# ESW3120 register map
Vendor: Shanghai Eastsoft Microelectronics Co.,Ltd.; Series: ARMCM3; File version: 1.2
CPU: CM3 r2p1, little endian, MPU, no FPU, 4 interrupt priority bits
Registers are 32-bit, read-write, reset 0x0 unless marked. A register's access mark holds for its fields unless they carry their own. Offsets are from the block's base; [hi:lo] are bit positions; {n}, {i} and the like mark numbered series.

## DBGC
Base 0x4004A000
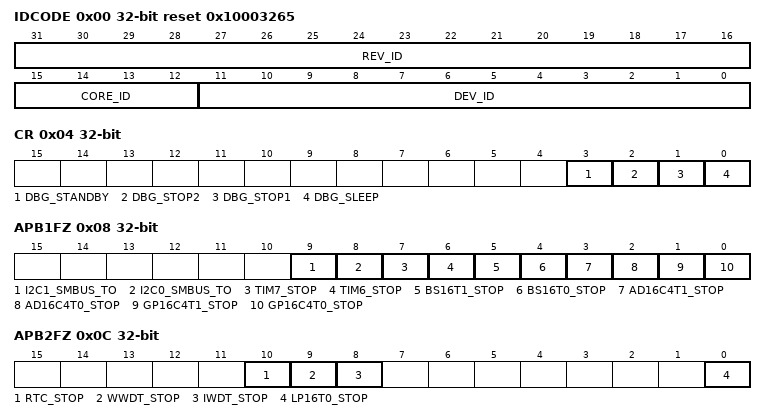
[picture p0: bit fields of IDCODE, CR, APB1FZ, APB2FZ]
0x00 IDCODE read reset 0x10003265
  [31:16] REV_ID, [15:12] CORE_ID, [11:0] DEV_ID
0x04 CR
  [3] DBG_STANDBY, [2] DBG_STOP2, [1] DBG_STOP1, [0] DBG_SLEEP
0x08 APB1FZ
  [9] I2C1_SMBUS_TO, [8] I2C0_SMBUS_TO, [7] TIM7_STOP, [6] TIM6_STOP, [5] BS16T1_STOP, [4] BS16T0_STOP, [3] AD16C4T1_STOP, [2] AD16C4T0_STOP, [1] GP16C4T1_STOP, [0] GP16C4T0_STOP
0x0C APB2FZ
  [10] RTC_STOP, [9] WWDT_STOP, [8] IWDT_STOP, [0] LP16T0_STOP
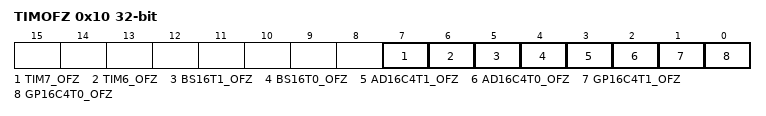
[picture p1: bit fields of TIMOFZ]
0x10 TIMOFZ
  [7] TIM7_OFZ, [6] TIM6_OFZ, [5] BS16T1_OFZ, [4] BS16T0_OFZ, [3] AD16C4T1_OFZ, [2] AD16C4T0_OFZ, [1] GP16C4T1_OFZ, [0] GP16C4T0_OFZ

## CRYPT
Base 0x40085800
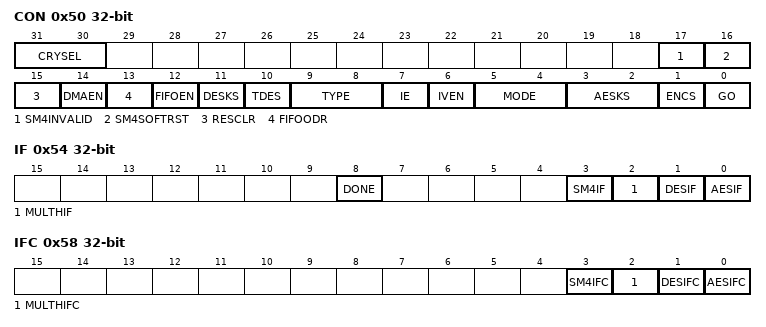
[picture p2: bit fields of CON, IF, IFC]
0x50 CON write1
  [31:30] CRYSEL rw, [17] SM4INVALID write, [16] SM4SOFTRST rw, [15] RESCLR, [14] DMAEN rw, [13] FIFOODR rw, [12] FIFOEN rw, [11] DESKS rw, [10] TDES rw, [9:8] TYPE rw, [7] IE rw, [6] IVEN rw, [5:4] MODE rw, [3:2] AESKS rw, [1] ENCS rw, [0] GO
0x54 IF read
  [8] DONE, [3] SM4IF, [2] MULTHIF, [1] DESIF, [0] AESIF
0x58 IFC write1
  [3] SM4IFC, [2] MULTHIFC, [1] DESIFC, [0] AESIFC
0x5C FIFO

## CRC
Base 0x40085000
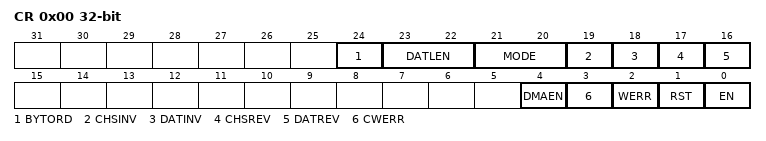
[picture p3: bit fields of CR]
0x00 CR
  [24] BYTORD, [23:22] DATLEN, [21:20] MODE, [19] CHSINV, [18] DATINV, [17] CHSREV, [16] DATREV, [4] DMAEN, [3] CWERR write1, [2] WERR read, [1] RST write1, [0] EN
0x04 DATA
0x08 SEED reset 0xFFFFFFFF
0x0C CHECKSUM read

## CMU
Base 0x40080400
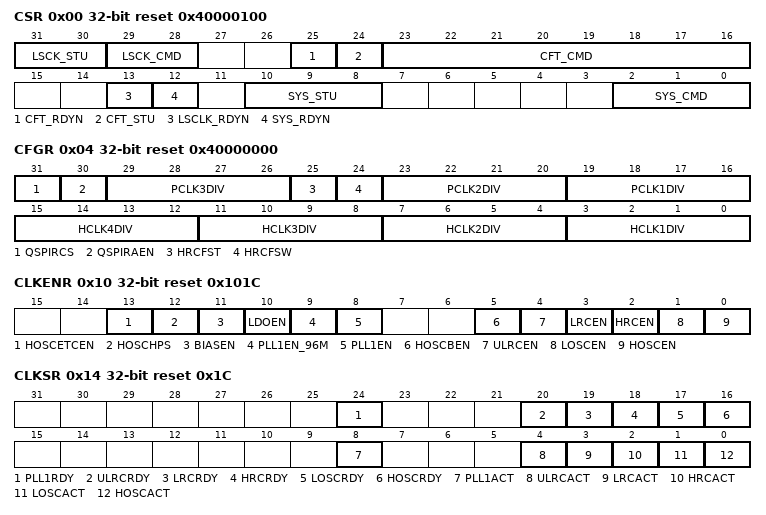
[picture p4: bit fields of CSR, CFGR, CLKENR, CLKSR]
0x00 CSR write reset 0x40000100
  [31:30] LSCK_STU read, [29:28] LSCK_CMD, [25] CFT_RDYN read, [24] CFT_STU read, [23:16] CFT_CMD, [13] LSCLK_RDYN read, [12] SYS_RDYN read, [10:8] SYS_STU read, [2:0] SYS_CMD
0x04 CFGR reset 0x40000000
  [31] QSPIRCS, [30] QSPIRAEN, [29:26] PCLK3DIV, [25] HRCFST read, [24] HRCFSW, [23:20] PCLK2DIV, [19:16] PCLK1DIV, [4n-1:4n-4] HCLK{n}DIV (n=1..4)
0x10 CLKENR reset 0x101C
  [13] HOSCETCEN, [12] HOSCHPS, [11] BIASEN, [10] LDOEN, [9] PLL1EN_96M, [8] PLL1EN, [5] HOSCBEN, [4] ULRCEN, [3] LRCEN, [2] HRCEN, [1] LOSCEN, [0] HOSCEN
0x14 CLKSR read reset 0x1C
  [24] PLL1RDY, [20] ULRCRDY, [19] LRCRDY, [18] HRCRDY, [17] LOSCRDY, [16] HOSCRDY, [8] PLL1ACT, [4] ULRCACT, [3] LRCACT, [2] HRCACT, [1] LOSCACT, [0] HOSCACT
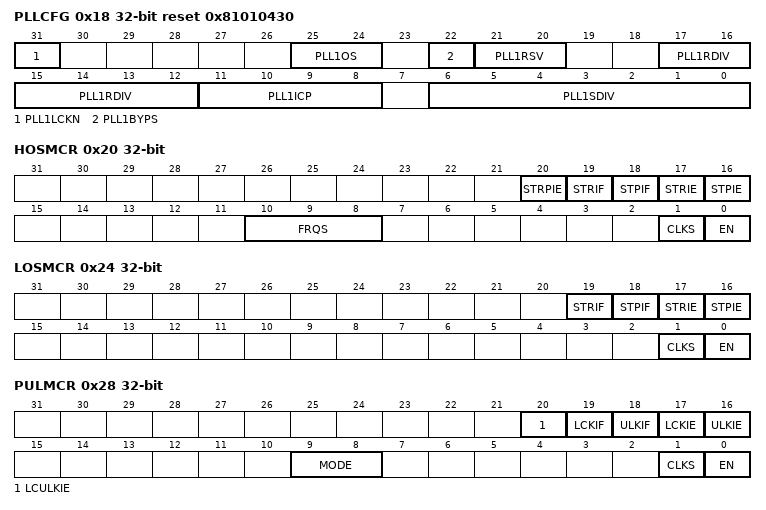
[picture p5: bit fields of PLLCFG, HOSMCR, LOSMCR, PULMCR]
0x18 PLLCFG reset 0x81010430
  [31] PLL1LCKN read, [25:24] PLL1OS, [22] PLL1BYPS, [21:20] PLL1RSV, [17:12] PLL1RDIV, [11:8] PLL1ICP, [6:0] PLL1SDIV
0x20 HOSMCR
  [20] STRPIE, [19] STRIF read-clear-write1, [18] STPIF read-clear-write1, [17] STRIE, [16] STPIE, [10:8] FRQS, [1] CLKS read, [0] EN
0x24 LOSMCR read
  [19] STRIF read-clear-write1, [18] STPIF read-clear-write1, [17] STRIE rw, [16] STPIE rw, [1] CLKS, [0] EN
0x28 PULMCR
  [20] LCULKIE, [19] LCKIF read-clear-write1, [18] ULKIF read-clear-write1, [17] LCKIE, [16] ULKIE, [9:8] MODE, [1] CLKS read, [0] EN
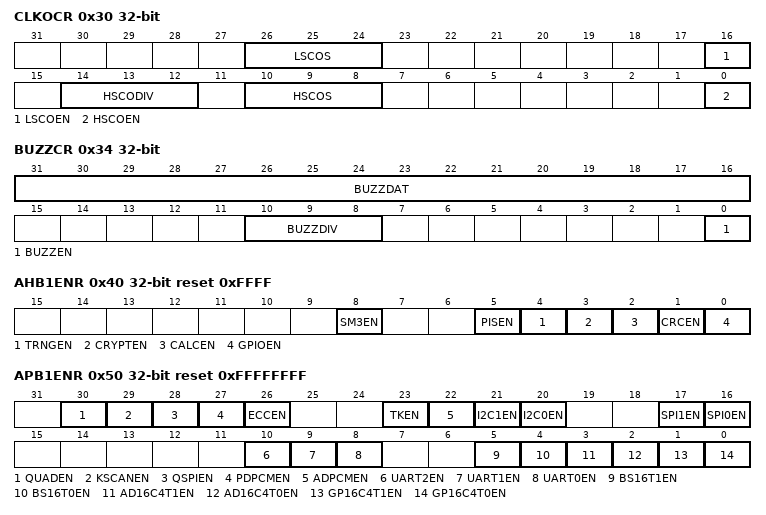
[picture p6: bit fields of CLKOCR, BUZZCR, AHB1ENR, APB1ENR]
0x30 CLKOCR
  [26:24] LSCOS, [16] LSCOEN, [14:12] HSCODIV, [10:8] HSCOS, [0] HSCOEN
0x34 BUZZCR
  [31:16] BUZZDAT, [10:8] BUZZDIV, [0] BUZZEN
0x40 AHB1ENR reset 0xFFFF
  [8] SM3EN, [5] PISEN, [4] TRNGEN, [3] CRYPTEN, [2] CALCEN, [1] CRCEN, [0] GPIOEN
0x50 APB1ENR reset 0xFFFFFFFF
  [30] QUADEN, [29] KSCANEN, [28] QSPIEN, [27] PDPCMEN, [26] ECCEN, [23] TKEN, [22] ADPCMEN, [21] I2C1EN, [20] I2C0EN, [17] SPI1EN, [16] SPI0EN, [10] UART2EN, [9] UART1EN, [8] UART0EN, [5] BS16T1EN, [4] BS16T0EN, [3] AD16C4T1EN, [2] AD16C4T0EN, [1] GP16C4T1EN, [0] GP16C4T0EN
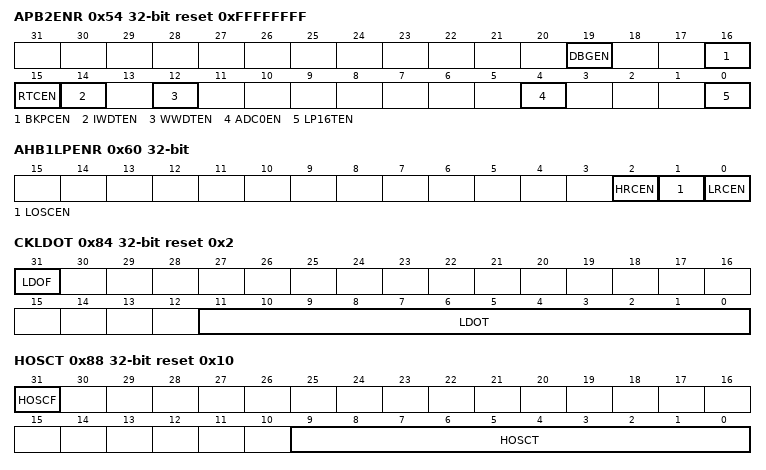
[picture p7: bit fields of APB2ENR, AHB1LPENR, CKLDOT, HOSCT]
0x54 APB2ENR reset 0xFFFFFFFF
  [19] DBGEN, [16] BKPCEN, [15] RTCEN, [14] IWDTEN, [12] WWDTEN, [4] ADC0EN, [0] LP16TEN
0x60 AHB1LPENR
  [2] HRCEN, [1] LOSCEN, [0] LRCEN
0x80 PERICR
  [10:8] LP16TCS
0x84 CKLDOT reset 0x2
  [31] LDOF read, [11:0] LDOT
0x88 HOSCT reset 0x10
  [31] HOSCF read, [9:0] HOSCT
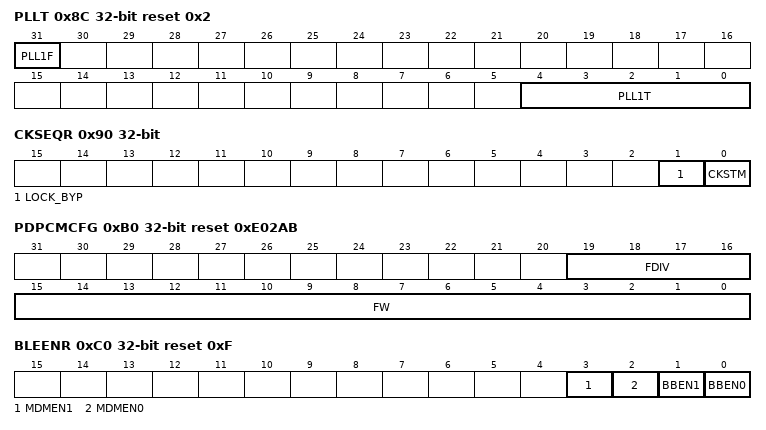
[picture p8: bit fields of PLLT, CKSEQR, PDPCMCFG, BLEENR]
0x8C PLLT reset 0x2
  [31] PLL1F read, [4:0] PLL1T
0x90 CKSEQR
  [1] LOCK_BYP, [0] CKSTM
0xB0 PDPCMCFG reset 0xE02AB
  [19:16] FDIV, [15:0] FW
0xC0 BLEENR reset 0xF
  [3] MDMEN1, [2] MDMEN0, [1] BBEN1, [0] BBEN0
0xC4 BLECFG reset 0x3
  [1:0] BBMCKS
0xC8 BLECKS reset 0xC
  [5:0] BBSCKS
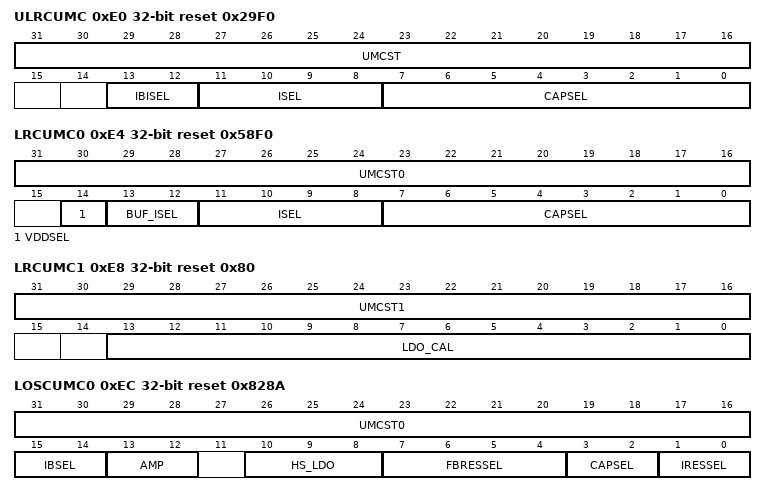
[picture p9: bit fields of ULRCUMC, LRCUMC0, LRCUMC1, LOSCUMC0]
0xE0 ULRCUMC reset 0x29F0
  [31:16] UMCST, [13:12] IBISEL, [11:8] ISEL, [7:0] CAPSEL
0xE4 LRCUMC0 reset 0x58F0
  [31:16] UMCST0, [14] VDDSEL, [13:12] BUF_ISEL, [11:8] ISEL, [7:0] CAPSEL
0xE8 LRCUMC1 reset 0x80
  [31:16] UMCST1, [13:0] LDO_CAL
0xEC LOSCUMC0 reset 0x828A
  [31:16] UMCST0, [15:14] IBSEL, [13:12] AMP, [10:8] HS_LDO, [7:4] FBRESSEL, [3:2] CAPSEL, [1:0] IRESSEL
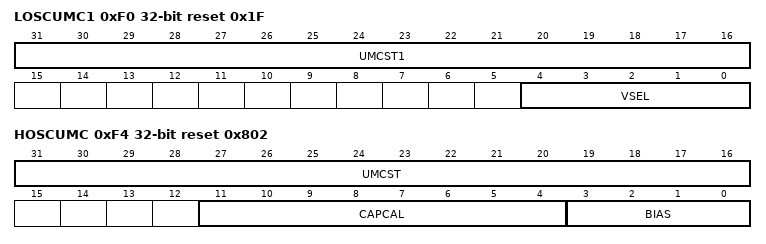
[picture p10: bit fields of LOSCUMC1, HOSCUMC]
0xF0 LOSCUMC1 reset 0x1F
  [31:16] UMCST1, [4:0] VSEL
0xF4 HOSCUMC reset 0x802
  [31:16] UMCST, [11:4] CAPCAL, [3:0] BIAS
